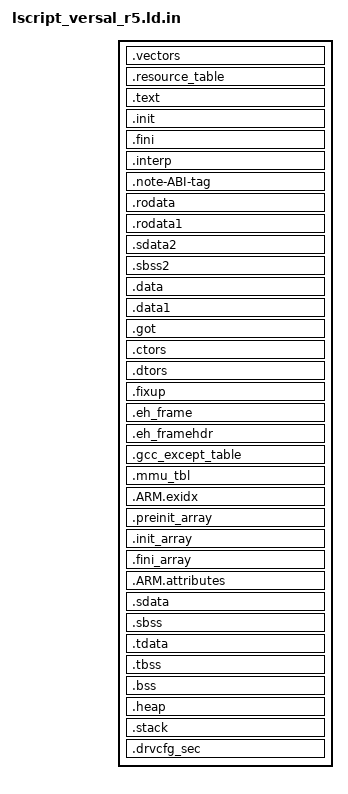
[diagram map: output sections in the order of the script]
/******************************************************************************
* Copyright (C) 2024 Advanced Micro Devices, Inc.  All rights reserved.
* SPDX-License-Identifier: MIT
******************************************************************************/

_STACK_SIZE = DEFINED(_STACK_SIZE) ? _STACK_SIZE : @STACK_SIZE@;
_HEAP_SIZE = DEFINED(_HEAP_SIZE) ? _HEAP_SIZE : @HEAP_SIZE@;

_ABORT_STACK_SIZE = DEFINED(_ABORT_STACK_SIZE) ? _ABORT_STACK_SIZE : 1024;
_SUPERVISOR_STACK_SIZE = DEFINED(_SUPERVISOR_STACK_SIZE) ? _SUPERVISOR_STACK_SIZE : 2048;
_IRQ_STACK_SIZE = DEFINED(_IRQ_STACK_SIZE) ? _IRQ_STACK_SIZE : 1024;
_FIQ_STACK_SIZE = DEFINED(_FIQ_STACK_SIZE) ? _FIQ_STACK_SIZE : 1024;
_UNDEF_STACK_SIZE = DEFINED(_UNDEF_STACK_SIZE) ? _UNDEF_STACK_SIZE : 1024;

@MEMORY_SECTION@

ENTRY(_vector_table)

/* Define the sections, and where they are mapped in memory */

SECTIONS
{
.vectors : {
   KEEP (*(.vectors))
   *(.boot)
} > psv_r5_0_atcm_MEM_0

.resource_table @RSC_TABLE@ : {
. = ALIGN(4);
*(.resource_table)
} > @DDR@

.text @RSC_TABLE@ + 0x100 : {
   *(.text)
   *(.text.*)
   *(.gnu.linkonce.t.*)
   *(.plt)
   *(.gnu_warning)
   *(.gcc_execpt_table)
   *(.glue_7)
   *(.glue_7t)
   *(.vfp11_veneer)
   *(.ARM.extab)
   *(.gnu.linkonce.armextab.*)
} > @DDR@

.init : {
   KEEP (*(.init))
} > psv_r5_0_btcm_MEM_0

.fini : {
   KEEP (*(.fini))
} > psv_r5_0_btcm_MEM_0

.interp : {
   KEEP (*(.interp))
} > psv_r5_0_btcm_MEM_0
.note-ABI-tag : {
   KEEP (*(.note-ABI-tag))
} > psv_r5_0_btcm_MEM_0

.rodata : {
   __rodata_start = .;
   *(.rodata)
   *(.rodata.*)
   *(.gnu.linkonce.r.*)
   __rodata_end = .;
} > psv_r5_0_btcm_MEM_0

.rodata1 : {
   __rodata1_start = .;
   *(.rodata1)
   *(.rodata1.*)
   __rodata1_end = .;
} > psv_r5_0_btcm_MEM_0

.sdata2 : {
   __sdata2_start = .;
   *(.sdata2)
   *(.sdata2.*)
   *(.gnu.linkonce.s2.*)
   __sdata2_end = .;
} > psv_r5_0_btcm_MEM_0

.sbss2 : {
   __sbss2_start = .;
   *(.sbss2)
   *(.sbss2.*)
   *(.gnu.linkonce.sb2.*)
   __sbss2_end = .;
} > psv_r5_0_btcm_MEM_0

.data : {
   __data_start = .;
   *(.data)
   *(.data.*)
   *(.gnu.linkonce.d.*)
   *(.jcr)
   *(.got)
   *(.got.plt)
   __data_end = .;
} > psv_r5_0_btcm_MEM_0

.data1 : {
   __data1_start = .;
   *(.data1)
   *(.data1.*)
   __data1_end = .;
} > psv_r5_0_btcm_MEM_0

.got : {
   *(.got)
} > psv_r5_0_btcm_MEM_0

.ctors : {
   __CTOR_LIST__ = .;
   ___CTORS_LIST___ = .;
   KEEP (*crtbegin.o(.ctors))
   KEEP (*(EXCLUDE_FILE(*crtend.o) .ctors))
   KEEP (*(SORT(.ctors.*)))
   KEEP (*(.ctors))
   __CTOR_END__ = .;
   ___CTORS_END___ = .;
} > psv_r5_0_btcm_MEM_0

.dtors : {
   __DTOR_LIST__ = .;
   ___DTORS_LIST___ = .;
   KEEP (*crtbegin.o(.dtors))
   KEEP (*(EXCLUDE_FILE(*crtend.o) .dtors))
   KEEP (*(SORT(.dtors.*)))
   KEEP (*(.dtors))
   __DTOR_END__ = .;
   ___DTORS_END___ = .;
} > psv_r5_0_btcm_MEM_0

.fixup : {
   __fixup_start = .;
   *(.fixup)
   __fixup_end = .;
} > psv_r5_0_btcm_MEM_0

.eh_frame : {
   *(.eh_frame)
} > psv_r5_0_btcm_MEM_0

.eh_framehdr : {
   __eh_framehdr_start = .;
   *(.eh_framehdr)
   __eh_framehdr_end = .;
} > psv_r5_0_btcm_MEM_0

.gcc_except_table : {
   *(.gcc_except_table)
} > psv_r5_0_btcm_MEM_0

.mmu_tbl (ALIGN(16384)) : {
   __mmu_tbl_start = .;
   *(.mmu_tbl)
   __mmu_tbl_end = .;
} > psv_r5_0_btcm_MEM_0

.ARM.exidx : {
   __exidx_start = .;
   *(.ARM.exidx*)
   *(.gnu.linkonce.armexidix.*.*)
   __exidx_end = .;
} > psv_r5_0_btcm_MEM_0

.preinit_array : {
   __preinit_array_start = .;
   KEEP (*(SORT(.preinit_array.*)))
   KEEP (*(.preinit_array))
   __preinit_array_end = .;
} > psv_r5_0_btcm_MEM_0

.init_array : {
   __init_array_start = .;
   KEEP (*(SORT(.init_array.*)))
   KEEP (*(.init_array))
   __init_array_end = .;
} > psv_r5_0_btcm_MEM_0

.fini_array : {
   __fini_array_start = .;
   KEEP (*(SORT(.fini_array.*)))
   KEEP (*(.fini_array))
   __fini_array_end = .;
} > psv_r5_0_btcm_MEM_0

.ARM.attributes : {
   __ARM.attributes_start = .;
   *(.ARM.attributes)
   __ARM.attributes_end = .;
} > psv_r5_0_btcm_MEM_0

.sdata : {
   __sdata_start = .;
   *(.sdata)
   *(.sdata.*)
   *(.gnu.linkonce.s.*)
   __sdata_end = .;
} > psv_r5_0_btcm_MEM_0

.sbss (NOLOAD) : {
   __sbss_start = .;
   *(.sbss)
   *(.sbss.*)
   *(.gnu.linkonce.sb.*)
   __sbss_end = .;
} > psv_r5_0_btcm_MEM_0

.tdata : {
   __tdata_start = .;
   *(.tdata)
   *(.tdata.*)
   *(.gnu.linkonce.td.*)
   __tdata_end = .;
} > psv_r5_0_btcm_MEM_0

.tbss : {
   __tbss_start = .;
   *(.tbss)
   *(.tbss.*)
   *(.gnu.linkonce.tb.*)
   __tbss_end = .;
} > psv_r5_0_btcm_MEM_0

.bss (NOLOAD) : {
   . = ALIGN(4);
   __bss_start__ = .;
   *(.bss)
   *(.bss.*)
   *(.gnu.linkonce.b.*)
   *(COMMON)
   . = ALIGN(4);
   __bss_end__ = .;
} > @DDR@

_SDA_BASE_ = __sdata_start + ((__sbss_end - __sdata_start) / 2 );

_SDA2_BASE_ = __sdata2_start + ((__sbss2_end - __sdata2_start) / 2 );

/* Generate Stack and Heap definitions */


.heap (NOLOAD) : {
   . = ALIGN(16);
   _heap = .;
   HeapBase = .;
   _heap_start = .;
   . += _HEAP_SIZE;
   _heap_end = .;
   HeapLimit = .;
} > psv_r5_0_btcm_MEM_0

.stack (NOLOAD) : {
   . = ALIGN(16);
   _stack_end = .;
   . += _STACK_SIZE;
   _stack = .;
   __stack = _stack;
   . = ALIGN(16);
   _irq_stack_end = .;
   . += _IRQ_STACK_SIZE;
   __irq_stack = .;
   _supervisor_stack_end = .;
   . += _SUPERVISOR_STACK_SIZE;
   . = ALIGN(16);
   __supervisor_stack = .;
   _abort_stack_end = .;
   . += _ABORT_STACK_SIZE;
   . = ALIGN(16);
   __abort_stack = .;
   _fiq_stack_end = .;
   . += _FIQ_STACK_SIZE;
   . = ALIGN(16);
   __fiq_stack = .;
   _undef_stack_end = .;
   . += _UNDEF_STACK_SIZE;
   . = ALIGN(16);
   __undef_stack = .;
} > psv_r5_0_btcm_MEM_0

.drvcfg_sec : {
    . = ALIGN(8);
     __drvcfgsecdata_start = .;
    KEEP (*(.drvcfg_sec))
    __drvcfgsecdata_end = .;
    __drvcfgsecdata_size = __drvcfgsecdata_end - __drvcfgsecdata_start;
} > psv_r5_0_btcm_MEM_0


end = .;
}
